AUTOSAR XML (schema 4-0-3)
standard types defined: UInt8, UInt16
package /ComponentType
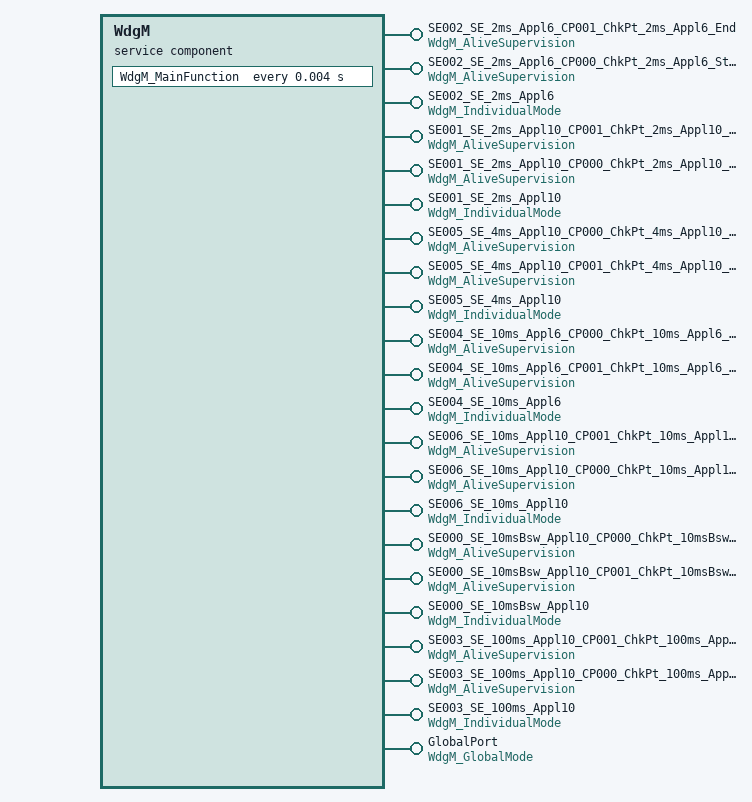
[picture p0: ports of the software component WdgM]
  service sw component type WdgM: category=SERVICE_COMPONENT
    22 x provide port:
      SE002_SE_2ms_Appl6_CP001_ChkPt_2ms_Appl6_End: provided-interface=WdgM_AliveSupervision  # P-Port Prototype for Supervised Entity SE_2ms_Appl6 with ID 2 and Checkpoint ChkPt_2ms_Appl6_End with ID 1.
      SE002_SE_2ms_Appl6_CP000_ChkPt_2ms_Appl6_Strt: provided-interface=WdgM_AliveSupervision  # P-Port Prototype for Supervised Entity SE_2ms_Appl6 with ID 2 and Checkpoint ChkPt_2ms_Appl6_Strt with ID 0.
      SE002_SE_2ms_Appl6: provided-interface=WdgM_IndividualMode  # P-Port Prototype for Supervised Entity SE_2ms_Appl6 with ID 2
      SE001_SE_2ms_Appl10_CP001_ChkPt_2ms_Appl10_End: provided-interface=WdgM_AliveSupervision  # P-Port Prototype for Supervised Entity SE_2ms_Appl10 with ID 1 and Checkpoint ChkPt_2ms_Appl10_End with ID 1.
      SE001_SE_2ms_Appl10_CP000_ChkPt_2ms_Appl10_Strt: provided-interface=WdgM_AliveSupervision  # P-Port Prototype for Supervised Entity SE_2ms_Appl10 with ID 1 and Checkpoint ChkPt_2ms_Appl10_Strt with ID 0.
      SE001_SE_2ms_Appl10: provided-interface=WdgM_IndividualMode  # P-Port Prototype for Supervised Entity SE_2ms_Appl10 with ID 1
      SE005_SE_4ms_Appl10_CP000_ChkPt_4ms_Appl10_Strt: provided-interface=WdgM_AliveSupervision  # P-Port Prototype for Supervised Entity SE_4ms_Appl10 with ID 5 and Checkpoint ChkPt_4ms_Appl10_Strt with ID 0.
      SE005_SE_4ms_Appl10_CP001_ChkPt_4ms_Appl10_End: provided-interface=WdgM_AliveSupervision  # P-Port Prototype for Supervised Entity SE_4ms_Appl10 with ID 5 and Checkpoint ChkPt_4ms_Appl10_End with ID 1.
      SE005_SE_4ms_Appl10: provided-interface=WdgM_IndividualMode  # P-Port Prototype for Supervised Entity SE_4ms_Appl10 with ID 5
      SE004_SE_10ms_Appl6_CP000_ChkPt_10ms_Appl6_Strt: provided-interface=WdgM_AliveSupervision  # P-Port Prototype for Supervised Entity SE_10ms_Appl6 with ID 4 and Checkpoint ChkPt_10ms_Appl6_Strt with ID 0.
      SE004_SE_10ms_Appl6_CP001_ChkPt_10ms_Appl6_End: provided-interface=WdgM_AliveSupervision  # P-Port Prototype for Supervised Entity SE_10ms_Appl6 with ID 4 and Checkpoint ChkPt_10ms_Appl6_End with ID 1.
      SE004_SE_10ms_Appl6: provided-interface=WdgM_IndividualMode  # P-Port Prototype for Supervised Entity SE_10ms_Appl6 with ID 4
      SE006_SE_10ms_Appl10_CP001_ChkPt_10ms_Appl10_End: provided-interface=WdgM_AliveSupervision  # P-Port Prototype for Supervised Entity SE_10ms_Appl10 with ID 6 and Checkpoint ChkPt_10ms_Appl10_End with ID 1.
      SE006_SE_10ms_Appl10_CP000_ChkPt_10ms_Appl10_Strt: provided-interface=WdgM_AliveSupervision  # P-Port Prototype for Supervised Entity SE_10ms_Appl10 with ID 6 and Checkpoint ChkPt_10ms_Appl10_Strt with ID 0.
      SE006_SE_10ms_Appl10: provided-interface=WdgM_IndividualMode  # P-Port Prototype for Supervised Entity SE_10ms_Appl10 with ID 6
      SE000_SE_10msBsw_Appl10_CP000_ChkPt_10msBsw_Appl10_Strt: provided-interface=WdgM_AliveSupervision  # P-Port Prototype for Supervised Entity SE_10msBsw_Appl10 with ID 0 and Checkpoint ChkPt_10msBsw_Appl10_Strt with ID 0.
      SE000_SE_10msBsw_Appl10_CP001_ChkPt_10msBsw_Appl10_End: provided-interface=WdgM_AliveSupervision  # P-Port Prototype for Supervised Entity SE_10msBsw_Appl10 with ID 0 and Checkpoint ChkPt_10msBsw_Appl10_End with ID 1.
      SE000_SE_10msBsw_Appl10: provided-interface=WdgM_IndividualMode  # P-Port Prototype for Supervised Entity SE_10msBsw_Appl10 with ID 0
      SE003_SE_100ms_Appl10_CP001_ChkPt_100ms_Appl10_End: provided-interface=WdgM_AliveSupervision  # P-Port Prototype for Supervised Entity SE_100ms_Appl10 with ID 3 and Checkpoint ChkPt_100ms_Appl10_End with ID 1.
      SE003_SE_100ms_Appl10_CP000_ChkPt_100ms_Appl10_Strt: provided-interface=WdgM_AliveSupervision  # P-Port Prototype for Supervised Entity SE_100ms_Appl10 with ID 3 and Checkpoint ChkPt_100ms_Appl10_Strt with ID 0.
      SE003_SE_100ms_Appl10: provided-interface=WdgM_IndividualMode  # P-Port Prototype for Supervised Entity SE_100ms_Appl10 with ID 3
      GlobalPort: provided-interface=WdgM_GlobalMode  # P-Port Prototype for Global Mode
    behavior WdgM_InternalBehavior
      operation invoked event V_WDGM_GMO: start-on-event=GetMode, operation=GlobalPort.GetMode
      operation invoked event V_WDGM_GGS: start-on-event=GetGlobalStatus, operation=GlobalPort.GetGlobalStatus
      operation invoked event V_WDGM_PRE: start-on-event=PerformReset, operation=GlobalPort.PerformReset
      timing event V_WDGM_MAI: start-on-event=WdgM_MainFunction, period=0.004
      35 x operation invoked event:
        V_WDGM_SE002_SE_2ms_Appl6_GLS: start-on-event=GetLocalStatus, operation=SE002_SE_2ms_Appl6.GetLocalStatus
        V_WDGM_SE002_SE_2ms_Appl6_ASE: start-on-event=ActivateSupervisionEntity, operation=SE002_SE_2ms_Appl6.ActivateSupervisionEntity
        V_WDGM_SE002_SE_2ms_Appl6_DSE: start-on-event=DeactivateSupervisionEntity, operation=SE002_SE_2ms_Appl6.DeactivateSupervisionEntity
        V_WDGM_SE002_SE_2ms_Appl6_CP001_ChkPt_2ms_Appl6_End_CPR: start-on-event=CheckpointReached, operation=SE002_SE_2ms_Appl6_CP001_ChkPt_2ms_Appl6_End.CheckpointReached
        V_WDGM_SE002_SE_2ms_Appl6_CP000_ChkPt_2ms_Appl6_Strt_CPR: start-on-event=CheckpointReached, operation=SE002_SE_2ms_Appl6_CP000_ChkPt_2ms_Appl6_Strt.CheckpointReached
        V_WDGM_SE001_SE_2ms_Appl10_GLS: start-on-event=GetLocalStatus, operation=SE001_SE_2ms_Appl10.GetLocalStatus
        V_WDGM_SE001_SE_2ms_Appl10_ASE: start-on-event=ActivateSupervisionEntity, operation=SE001_SE_2ms_Appl10.ActivateSupervisionEntity
        V_WDGM_SE001_SE_2ms_Appl10_DSE: start-on-event=DeactivateSupervisionEntity, operation=SE001_SE_2ms_Appl10.DeactivateSupervisionEntity
        V_WDGM_SE001_SE_2ms_Appl10_CP001_ChkPt_2ms_Appl10_End_CPR: start-on-event=CheckpointReached, operation=SE001_SE_2ms_Appl10_CP001_ChkPt_2ms_Appl10_End.CheckpointReached
        V_WDGM_SE001_SE_2ms_Appl10_CP000_ChkPt_2ms_Appl10_Strt_CPR: start-on-event=CheckpointReached, operation=SE001_SE_2ms_Appl10_CP000_ChkPt_2ms_Appl10_Strt.CheckpointReached
        V_WDGM_SE005_SE_4ms_Appl10_GLS: start-on-event=GetLocalStatus, operation=SE005_SE_4ms_Appl10.GetLocalStatus
        V_WDGM_SE005_SE_4ms_Appl10_ASE: start-on-event=ActivateSupervisionEntity, operation=SE005_SE_4ms_Appl10.ActivateSupervisionEntity
        V_WDGM_SE005_SE_4ms_Appl10_DSE: start-on-event=DeactivateSupervisionEntity, operation=SE005_SE_4ms_Appl10.DeactivateSupervisionEntity
        V_WDGM_SE005_SE_4ms_Appl10_CP000_ChkPt_4ms_Appl10_Strt_CPR: start-on-event=CheckpointReached, operation=SE005_SE_4ms_Appl10_CP000_ChkPt_4ms_Appl10_Strt.CheckpointReached
        V_WDGM_SE005_SE_4ms_Appl10_CP001_ChkPt_4ms_Appl10_End_CPR: start-on-event=CheckpointReached, operation=SE005_SE_4ms_Appl10_CP001_ChkPt_4ms_Appl10_End.CheckpointReached
        V_WDGM_SE004_SE_10ms_Appl6_GLS: start-on-event=GetLocalStatus, operation=SE004_SE_10ms_Appl6.GetLocalStatus
        V_WDGM_SE004_SE_10ms_Appl6_ASE: start-on-event=ActivateSupervisionEntity, operation=SE004_SE_10ms_Appl6.ActivateSupervisionEntity
        V_WDGM_SE004_SE_10ms_Appl6_DSE: start-on-event=DeactivateSupervisionEntity, operation=SE004_SE_10ms_Appl6.DeactivateSupervisionEntity
        V_WDGM_SE004_SE_10ms_Appl6_CP000_ChkPt_10ms_Appl6_Strt_CPR: start-on-event=CheckpointReached, operation=SE004_SE_10ms_Appl6_CP000_ChkPt_10ms_Appl6_Strt.CheckpointReached
        V_WDGM_SE004_SE_10ms_Appl6_CP001_ChkPt_10ms_Appl6_End_CPR: start-on-event=CheckpointReached, operation=SE004_SE_10ms_Appl6_CP001_ChkPt_10ms_Appl6_End.CheckpointReached
        V_WDGM_SE006_SE_10ms_Appl10_GLS: start-on-event=GetLocalStatus, operation=SE006_SE_10ms_Appl10.GetLocalStatus
        V_WDGM_SE006_SE_10ms_Appl10_ASE: start-on-event=ActivateSupervisionEntity, operation=SE006_SE_10ms_Appl10.ActivateSupervisionEntity
        V_WDGM_SE006_SE_10ms_Appl10_DSE: start-on-event=DeactivateSupervisionEntity, operation=SE006_SE_10ms_Appl10.DeactivateSupervisionEntity
        V_WDGM_SE006_SE_10ms_Appl10_CP001_ChkPt_10ms_Appl10_End_CPR: start-on-event=CheckpointReached, operation=SE006_SE_10ms_Appl10_CP001_ChkPt_10ms_Appl10_End.CheckpointReached
        V_WDGM_SE006_SE_10ms_Appl10_CP000_ChkPt_10ms_Appl10_Strt_CPR: start-on-event=CheckpointReached, operation=SE006_SE_10ms_Appl10_CP000_ChkPt_10ms_Appl10_Strt.CheckpointReached
        V_WDGM_SE000_SE_10msBsw_Appl10_GLS: start-on-event=GetLocalStatus, operation=SE000_SE_10msBsw_Appl10.GetLocalStatus
        V_WDGM_SE000_SE_10msBsw_Appl10_ASE: start-on-event=ActivateSupervisionEntity, operation=SE000_SE_10msBsw_Appl10.ActivateSupervisionEntity
        V_WDGM_SE000_SE_10msBsw_Appl10_DSE: start-on-event=DeactivateSupervisionEntity, operation=SE000_SE_10msBsw_Appl10.DeactivateSupervisionEntity
        V_WDGM_SE000_SE_10msBsw_Appl10_CP000_ChkPt_10msBsw_Appl10_Strt_CPR: start-on-event=CheckpointReached, operation=SE000_SE_10msBsw_Appl10_CP000_ChkPt_10msBsw_Appl10_Strt.CheckpointReached
        V_WDGM_SE000_SE_10msBsw_Appl10_CP001_ChkPt_10msBsw_Appl10_End_CPR: start-on-event=CheckpointReached, operation=SE000_SE_10msBsw_Appl10_CP001_ChkPt_10msBsw_Appl10_End.CheckpointReached
        V_WDGM_SE003_SE_100ms_Appl10_GLS: start-on-event=GetLocalStatus, operation=SE003_SE_100ms_Appl10.GetLocalStatus
        V_WDGM_SE003_SE_100ms_Appl10_ASE: start-on-event=ActivateSupervisionEntity, operation=SE003_SE_100ms_Appl10.ActivateSupervisionEntity
        V_WDGM_SE003_SE_100ms_Appl10_DSE: start-on-event=DeactivateSupervisionEntity, operation=SE003_SE_100ms_Appl10.DeactivateSupervisionEntity
        V_WDGM_SE003_SE_100ms_Appl10_CP001_ChkPt_100ms_Appl10_End_CPR: start-on-event=CheckpointReached, operation=SE003_SE_100ms_Appl10_CP001_ChkPt_100ms_Appl10_End.CheckpointReached
        V_WDGM_SE003_SE_100ms_Appl10_CP000_ChkPt_100ms_Appl10_Strt_CPR: start-on-event=CheckpointReached, operation=SE003_SE_100ms_Appl10_CP000_ChkPt_100ms_Appl10_Strt.CheckpointReached
      port-api-options:
        {port-arg-values=[{value=2, value-type=WdgM_SupervisedEntityIdType}, {value=1, value-type=WdgM_CheckpointIdType}], port=SE002_SE_2ms_Appl6_CP001_ChkPt_2ms_Appl6_End}
        {port-arg-values=[{value=2, value-type=WdgM_SupervisedEntityIdType}, {value=0, value-type=WdgM_CheckpointIdType}], port=SE002_SE_2ms_Appl6_CP000_ChkPt_2ms_Appl6_Strt}
        {port-defined-argument-value{value=2, value-type=WdgM_SupervisedEntityIdType}, port=SE002_SE_2ms_Appl6}
        {port-arg-values=[{value=1, value-type=WdgM_SupervisedEntityIdType}, {value=1, value-type=WdgM_CheckpointIdType}], port=SE001_SE_2ms_Appl10_CP001_ChkPt_2ms_Appl10_End}
        {port-arg-values=[{value=1, value-type=WdgM_SupervisedEntityIdType}, {value=0, value-type=WdgM_CheckpointIdType}], port=SE001_SE_2ms_Appl10_CP000_ChkPt_2ms_Appl10_Strt}
        {port-defined-argument-value{value=1, value-type=WdgM_SupervisedEntityIdType}, port=SE001_SE_2ms_Appl10}
        {port-arg-values=[{value=5, value-type=WdgM_SupervisedEntityIdType}, {value=0, value-type=WdgM_CheckpointIdType}], port=SE005_SE_4ms_Appl10_CP000_ChkPt_4ms_Appl10_Strt}
        {port-arg-values=[{value=5, value-type=WdgM_SupervisedEntityIdType}, {value=1, value-type=WdgM_CheckpointIdType}], port=SE005_SE_4ms_Appl10_CP001_ChkPt_4ms_Appl10_End}
        {port-defined-argument-value{value=5, value-type=WdgM_SupervisedEntityIdType}, port=SE005_SE_4ms_Appl10}
        {port-arg-values=[{value=4, value-type=WdgM_SupervisedEntityIdType}, {value=0, value-type=WdgM_CheckpointIdType}], port=SE004_SE_10ms_Appl6_CP000_ChkPt_10ms_Appl6_Strt}
        {port-arg-values=[{value=4, value-type=WdgM_SupervisedEntityIdType}, {value=1, value-type=WdgM_CheckpointIdType}], port=SE004_SE_10ms_Appl6_CP001_ChkPt_10ms_Appl6_End}
        {port-defined-argument-value{value=4, value-type=WdgM_SupervisedEntityIdType}, port=SE004_SE_10ms_Appl6}
        {port-arg-values=[{value=6, value-type=WdgM_SupervisedEntityIdType}, {value=1, value-type=WdgM_CheckpointIdType}], port=SE006_SE_10ms_Appl10_CP001_ChkPt_10ms_Appl10_End}
        {port-arg-values=[{value=6, value-type=WdgM_SupervisedEntityIdType}, {value=0, value-type=WdgM_CheckpointIdType}], port=SE006_SE_10ms_Appl10_CP000_ChkPt_10ms_Appl10_Strt}
        {port-defined-argument-value{value=6, value-type=WdgM_SupervisedEntityIdType}, port=SE006_SE_10ms_Appl10}
        {port-arg-values=[{value=0, value-type=WdgM_SupervisedEntityIdType}, {value=0, value-type=WdgM_CheckpointIdType}], port=SE000_SE_10msBsw_Appl10_CP000_ChkPt_10msBsw_Appl10_Strt}
        {port-arg-values=[{value=0, value-type=WdgM_SupervisedEntityIdType}, {value=1, value-type=WdgM_CheckpointIdType}], port=SE000_SE_10msBsw_Appl10_CP001_ChkPt_10msBsw_Appl10_End}
        {port-defined-argument-value{value=0, value-type=WdgM_SupervisedEntityIdType}, port=SE000_SE_10msBsw_Appl10}
        {port-arg-values=[{value=3, value-type=WdgM_SupervisedEntityIdType}, {value=1, value-type=WdgM_CheckpointIdType}], port=SE003_SE_100ms_Appl10_CP001_ChkPt_100ms_Appl10_End}
        {port-arg-values=[{value=3, value-type=WdgM_SupervisedEntityIdType}, {value=0, value-type=WdgM_CheckpointIdType}], port=SE003_SE_100ms_Appl10_CP000_ChkPt_100ms_Appl10_Strt}
        {port-defined-argument-value{value=3, value-type=WdgM_SupervisedEntityIdType}, port=SE003_SE_100ms_Appl10}
      8 x runnable, all with can-be-invoked-concurrently=true:
        GetMode: symbol=WdgM_GetMode
        CheckpointReached: symbol=WdgM_CheckpointReached
        GetLocalStatus: symbol=WdgM_GetLocalStatus
        ActivateSupervisionEntity: symbol=WdgM_ActivateSupervisionEntity
        DeactivateSupervisionEntity: symbol=WdgM_DeactivateSupervisionEntity
        GetGlobalStatus: symbol=WdgM_GetGlobalStatus
        PerformReset: symbol=WdgM_PerformReset
        WdgM_MainFunction
  swc implementation WdgM_Implementation: behavior=WdgM_InternalBehavior
package /ComponentType/DataTypes/BaseTypes
  5 x base type, all with base-type-encoding=NONE:
    WdgM_CheckpointIdType: base-type-size=16, native-declaration=uint16
    WdgM_GlobalStatusType: category=FIXED_LENGTH, base-type-size=8, native-declaration=uint8
    WdgM_LocalStatusType: category=FIXED_LENGTH, base-type-size=8, native-declaration=uint8
    WdgM_ModeType: category=FIXED_LENGTH, base-type-size=8, native-declaration=uint8
    WdgM_SupervisedEntityIdType: category=FIXED_LENGTH, base-type-size=16, native-declaration=uint16
package /PortInterface
  client server interface WdgM_AliveSupervision: is-service=true
    operation CheckpointReached: possible-error=WdgM_AliveSupervision/E_NOT_OK  # Indicates to the Watchdog Manager that a Checkpoint within a Supervised Entity has been reached.
    error E_NOT_OK: error-code=1
  client server interface WdgM_IndividualMode: is-service=true
    operation GetLocalStatus: possible-error=WdgM_IndividualMode/E_NOT_OK  # Returns the monitoring status of an individual Supervised Entity.
      arg Status: type=WdgM_LocalStatusType, direction=OUT
    operation ActivateSupervisionEntity: possible-error=WdgM_IndividualMode/E_NOT_OK  # This function activates the monitoring of the given Supervised Entity
    operation DeactivateSupervisionEntity: possible-error=WdgM_IndividualMode/E_NOT_OK  # This function deactivates the monitoring of the given Supervised Entity
    error E_NOT_OK: error-code=1
  client server interface WdgM_GlobalMode: is-service=true
    operation GetMode: possible-error=WdgM_GlobalMode/E_NOT_OK  # Returns the current mode of the Watchdog Manager.
      arg Mode: type=WdgM_ModeType, direction=OUT
    operation GetGlobalStatus: possible-error=WdgM_GlobalMode/E_NOT_OK  # Returns the global monitoring status of the Watchdog Manager.
      arg Status: type=WdgM_GlobalStatusType, direction=OUT
    operation PerformReset: possible-error=WdgM_GlobalMode/E_NOT_OK  # Instructs the Watchdog Manager to cause a watchdog reset.
    error E_NOT_OK: error-code=1
package /DataType
  5 x impl type, all with category=VALUE:
    WdgM_SupervisedEntityIdType: base-type=UInt8, range raw 0..255
    WdgM_CheckpointIdType: base-type=UInt16, range raw 0..65535
    WdgM_ModeType: base-type=UInt8, range raw 0..255
    WdgM_LocalStatusType: base-type=WdgM_LocalStatusType, compu {0=WDGM_LOCAL_STATUS_OK, 1=WDGM_LOCAL_STATUS_FAILED, 2=WDGM_LOCAL_STATUS_EXPIRED, 4=WDGM_LOCAL_STATUS_DEACTIVATED}, range raw 0..255
    WdgM_GlobalStatusType: base-type=WdgM_GlobalStatusType, compu {0=WDGM_GLOBAL_STATUS_OK, 1=WDGM_GLOBAL_STATUS_FAILED, 2=WDGM_GLOBAL_STATUS_EXPIRED, 3=WDGM_GLOBAL_STATUS_STOPPED, 4=WDGM_GLOBAL_STATUS_DEACTIVATED}, range raw 0..255
